VERSION ""

NS_ :

BS_:

BU_: BMS LOGGER

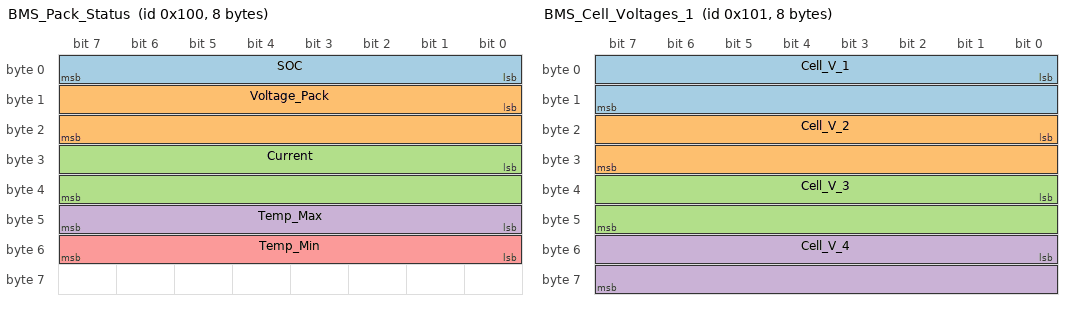
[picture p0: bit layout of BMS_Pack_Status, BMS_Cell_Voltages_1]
BO_ 256 BMS_Pack_Status: 8 BMS
 SG_ SOC : 0|8@1+ (1,0) [0|100] "%" LOGGER
 SG_ Voltage_Pack : 8|16@1+ (0.1,0) [0|600] "V" LOGGER
 SG_ Current : 24|16@1+ (0.1,-3000) [-3000|3000] "A" LOGGER
 SG_ Temp_Max : 40|8@1+ (1,-40) [-40|215] "degC" LOGGER
 SG_ Temp_Min : 48|8@1+ (1,-40) [-40|215] "degC" LOGGER

BO_ 257 BMS_Cell_Voltages_1: 8 BMS
 SG_ Cell_V_1 : 0|16@1+ (0.001,2.0) [2|4.5] "V" LOGGER
 SG_ Cell_V_2 : 16|16@1+ (0.001,2.0) [2|4.5] "V" LOGGER
 SG_ Cell_V_3 : 32|16@1+ (0.001,2.0) [2|4.5] "V" LOGGER
 SG_ Cell_V_4 : 48|16@1+ (0.001,2.0) [2|4.5] "V" LOGGER

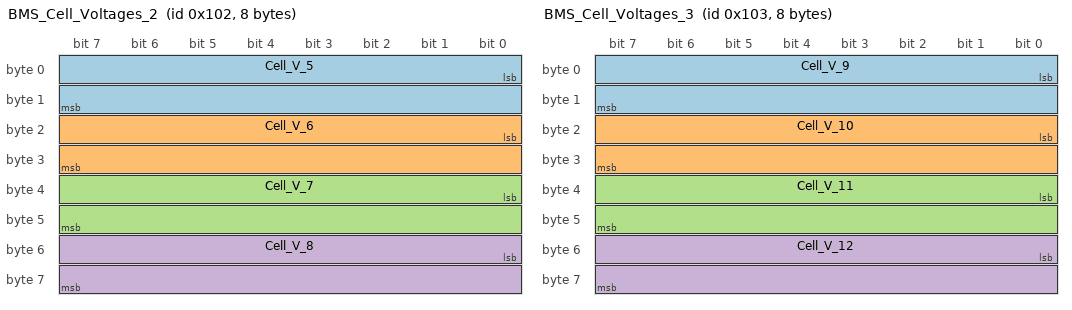
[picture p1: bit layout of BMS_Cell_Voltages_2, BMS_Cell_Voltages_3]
BO_ 258 BMS_Cell_Voltages_2: 8 BMS
 SG_ Cell_V_5 : 0|16@1+ (0.001,2.0) [2|4.5] "V" LOGGER
 SG_ Cell_V_6 : 16|16@1+ (0.001,2.0) [2|4.5] "V" LOGGER
 SG_ Cell_V_7 : 32|16@1+ (0.001,2.0) [2|4.5] "V" LOGGER
 SG_ Cell_V_8 : 48|16@1+ (0.001,2.0) [2|4.5] "V" LOGGER

BO_ 259 BMS_Cell_Voltages_3: 8 BMS
 SG_ Cell_V_9 : 0|16@1+ (0.001,2.0) [2|4.5] "V" LOGGER
 SG_ Cell_V_10 : 16|16@1+ (0.001,2.0) [2|4.5] "V" LOGGER
 SG_ Cell_V_11 : 32|16@1+ (0.001,2.0) [2|4.5] "V" LOGGER
 SG_ Cell_V_12 : 48|16@1+ (0.001,2.0) [2|4.5] "V" LOGGER

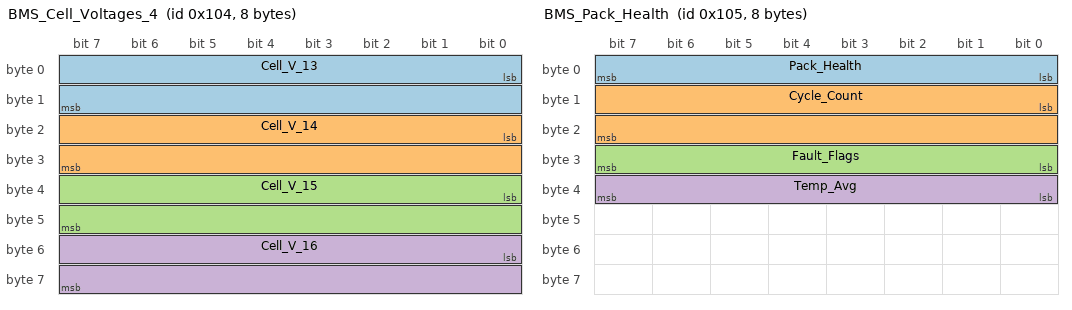
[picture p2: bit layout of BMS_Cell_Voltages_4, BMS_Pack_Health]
BO_ 260 BMS_Cell_Voltages_4: 8 BMS
 SG_ Cell_V_13 : 0|16@1+ (0.001,2.0) [2|4.5] "V" LOGGER
 SG_ Cell_V_14 : 16|16@1+ (0.001,2.0) [2|4.5] "V" LOGGER
 SG_ Cell_V_15 : 32|16@1+ (0.001,2.0) [2|4.5] "V" LOGGER
 SG_ Cell_V_16 : 48|16@1+ (0.001,2.0) [2|4.5] "V" LOGGER

BO_ 261 BMS_Pack_Health: 8 BMS
 SG_ Pack_Health : 0|8@1+ (1,0) [0|100] "%" LOGGER
 SG_ Cycle_Count : 8|16@1+ (1,0) [0|65535] "" LOGGER
 SG_ Fault_Flags : 24|8@1+ (1,0) [0|255] "" LOGGER
 SG_ Temp_Avg : 32|8@1+ (1,-40) [-40|215] "degC" LOGGER

CM_ BO_ 256 "Pack-level status: SOC, voltage, current, min/max temperatures";
CM_ BO_ 257 "Cell voltages 1-4";
CM_ BO_ 258 "Cell voltages 5-8";
CM_ BO_ 259 "Cell voltages 9-12";
CM_ BO_ 260 "Cell voltages 13-16";
CM_ BO_ 261 "Pack health: SOH, cycle count, fault bitmask, average temperature";

CM_ SG_ 256 SOC "State of Charge";
CM_ SG_ 256 Current "Pack current; positive = discharging";
CM_ SG_ 261 Pack_Health "State of Health (SOH)";
CM_ SG_ 261 Fault_Flags "Bit 0: cell over-temp, Bit 1: cell over-volt, Bit 2: cell under-volt, Bit 3: cell imbalance, Bit 4-7: reserved";
